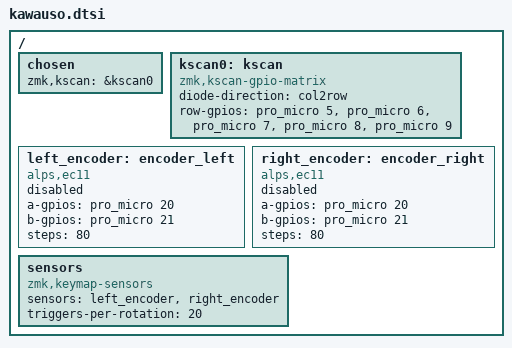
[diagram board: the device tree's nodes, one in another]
#include <dt-bindings/zmk/matrix_transform.h>

/ {
    chosen {
        zmk,kscan = &kscan0;
    };
    kscan0: kscan {
        compatible = "zmk,kscan-gpio-matrix";

        diode-direction = "col2row";
        row-gpios
            = <&pro_micro 5 (GPIO_ACTIVE_HIGH | GPIO_PULL_DOWN)> // Row A from the schematic file
            , <&pro_micro 6 (GPIO_ACTIVE_HIGH | GPIO_PULL_DOWN)> // Row B from the schematic file
            , <&pro_micro 7 (GPIO_ACTIVE_HIGH | GPIO_PULL_DOWN)> // Row C from the schematic file
            , <&pro_micro 8 (GPIO_ACTIVE_HIGH | GPIO_PULL_DOWN)> // Row D from the schematic file
            , <&pro_micro 9 (GPIO_ACTIVE_HIGH | GPIO_PULL_DOWN)> // Row E from the schematic file
            ;

    };
    left_encoder: encoder_left {
        compatible = "alps,ec11";
        a-gpios = <&pro_micro 20 (GPIO_ACTIVE_HIGH | GPIO_PULL_UP)>;
        b-gpios = <&pro_micro 21 (GPIO_ACTIVE_HIGH | GPIO_PULL_UP)>;
        steps = <80>;
        status = "disabled";
    };

    right_encoder: encoder_right {
        compatible = "alps,ec11";
        a-gpios = <&pro_micro 20 (GPIO_ACTIVE_HIGH | GPIO_PULL_UP)>;
        b-gpios = <&pro_micro 21 (GPIO_ACTIVE_HIGH | GPIO_PULL_UP)>;
        steps = <80>;
        status = "disabled";
    };
    sensors: sensors {
        compatible = "zmk,keymap-sensors";
        sensors = <&left_encoder &right_encoder>;
        triggers-per-rotation = <20>;
    };
};
